# D2522AA register map
Vendor: Dialog; Series: D2522AA; File version: 1.2
CPU: CM0 r1p0, little endian, MPU, FPU, 3 interrupt priority bits
Registers are 32-bit, read-write, reset 0x0 unless marked. A register's access mark holds for its fields unless they carry their own. Offsets are from the block's base; [hi:lo] are bit positions; 'fields as' and 'values as' point back to an identical list.

## CMAC_TIMER_SLP — CMAC_TIMER_SLP registers
Base 0x50010400
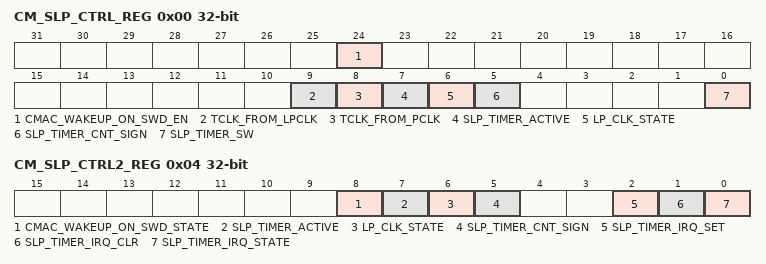
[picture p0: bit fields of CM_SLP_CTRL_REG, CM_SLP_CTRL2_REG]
0x00 CM_SLP_CTRL_REG — CMAC Sleep Control 1 (allowed to RMW)
  [24] CMAC_WAKEUP_ON_SWD_EN — If '1' then enable the generation of CMAC_WAKEUP_ON_SWD.
  [9] TCLK_FROM_LPCLK — The FW must be synchronized with LP_CLK negedge in order to change this bit.
  [8] TCLK_FROM_PCLK — The FW must be synchronized with LP_CLK negedge in order to change this bit.
  [7] SLP_TIMER_ACTIVE ro
  [6] LP_CLK_STATE ro — Current state of LP_CLK. Typically used only by System CPU. Refer also to CM_EV_LATCHED_REG->EV1C_LP_CLK_* and CM_SLP_CTRL2_REG->LP_CLK_STATE.
  [5] SLP_TIMER_CNT_SIGN ro — Refer to CM_SLP_CTRL2_REG->SLP_TIMER_CNT_SIGN.
  [0] SLP_TIMER_SW — The FW must be synchronized with LP_CLK negedge in order to change this bit. If 1: Initiate the sequence of stop counting with LL_TIMERx and start counting with the Sleep Timer. If 0: Initiate the sequence of stop counting with Sleep Timer and start counting with the LL_TIMERx. Writing a "1" will be effective only if SLP_TIMER_SEL_PCLK is written also with "0", regardless of the previous state of SLP_TIMER_SEL_PCLK. Writing a "0" will be effective only if SLP_TIMER_SEL_PCLK is written also with "1", regardless of the previous state of SLP_TIMER_SEL_PCLK. The end of the sequence is reported via SLP_TIMER_ACTIVE.
0x04 CM_SLP_CTRL2_REG — CMAC Sleep Control 2 (no RMW)
  [8] CMAC_WAKEUP_ON_SWD_STATE — Provides the current state of CMAC_WAKEUP_ON_SWD. Writing '1' will clear this bit. Writing '0' has no effect. When CM_SLP_CTRL_REG->CMAC_WAKEUP_ON_SWD_EN=1 and the Radio Power Domain is down and SYS_CTRL_REG->CMAC_DEBUGGER_ENABLE=1 then any negative edge on SWDCLK pin will set the CMAC_WAKEUP_ON_SWD. The CMAC_WAKEUP_ON_SWD logically OR-ed with SLP_TIMER_IRQ is connected to PDC and thus it is able to wake up the CMAC, allowing the connection of CMAC Cortex with the debugger.
  [7] SLP_TIMER_ACTIVE ro — Refer to CM_SLP_CTRL_REG->SLP_TIMER_ACTIVE
  [6] LP_CLK_STATE ro — Refer to CM_SLP_CTRL_REG->LP_CLK_STATE.
  [5] SLP_TIMER_CNT_SIGN ro — Provides the SLP_TIMER_CNT[32] bit, which corresponds to the sign bit.
  [2] SLP_TIMER_IRQ_SET — Writing '1' will cause the IRQ to be set. This field remains to '1' until the IRQ is set. Writing '0' has no effect. System CPU SW may use this field to force CMAC to wakeup through SLP_TIMER. Note that typically SW wakes up CMAC through the SYS2CMAC_IRQ (via PDC).
  [1] SLP_TIMER_IRQ_CLR — Writing '1' will cause the IRQ to be cleared. This field remains to '1' until the IRQ is cleared. Writing '0' has no effect. Note that clearing the IRQ is not possible as long as the Timer is "1", since the Expire event has higher priority.
  [0] SLP_TIMER_IRQ_STATE ro — Provides the current state of the CMAC Sleep Timer IRQ.
0x08 CM_SLP_TIMER_REG (reset mask 0x7FFFFFFF) — CMAC Sleep Timer
  [31:0] CM_SLP_TIMER_VALUE — The low 32 bits of the signed value of the 33 bit CMAC Sleep Timer. The sign bit 32 can be fetched via CM_SLP_CTRL_REG->SLP_TIMER_CNT_SIGN. It's possible to perform only 32-bit write access, while every write access will set the sign bit 32 to '0'. A read or write access with CM_SLP_CTRL_REG->TCLK_FROM_PCLK equal to 0 will cause a bus error. As long as the value is "1" then the expiration and the IRQ signal are asserted.

## CRG_COM — CRG_COM registers
Base 0x50020900
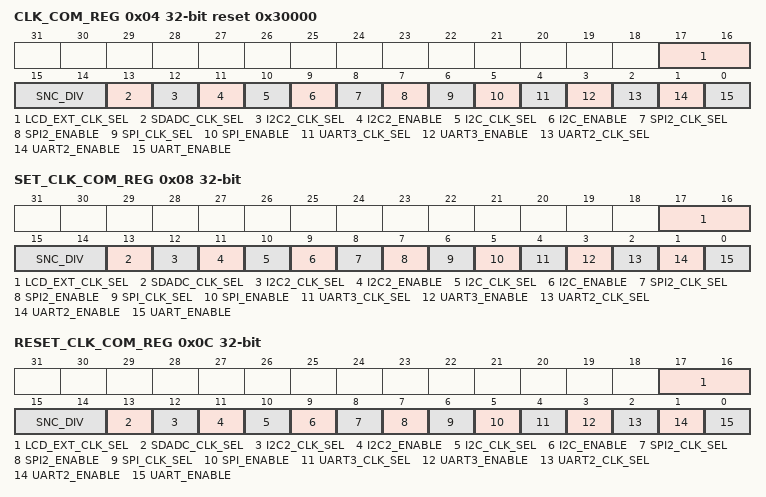
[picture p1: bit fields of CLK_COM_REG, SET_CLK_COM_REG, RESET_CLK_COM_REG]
0x04 CLK_COM_REG reset 0x30000 — Peripheral divider register
  [17:16] LCD_EXT_CLK_SEL — Select LCD external clock speed. 0x0: 1 Hz 0x1: 62.5 Hz 0x2: 125 Hz 0x3: off
  [15:14] SNC_DIV — Division factor for SNC, w.r.t. pclk setting 0x0 = divide by 1 0x1 = divide by 2 0x2 = divide by 4 0x3 = divide by 8
  [13] SDADC_CLK_SEL — Selects the clock source 1 = DIV1 clock 0 = DIVN clock
  [12] I2C2_CLK_SEL — Selects the clock source 1 = DIV1 clock 0 = DIVN clock
  [11] I2C2_ENABLE — Enables the clock
  [10] I2C_CLK_SEL — Selects the clock source 1 = DIV1 clock 0 = DIVN clock
  [9] I2C_ENABLE — Enables the clock
  [8] SPI2_CLK_SEL — Selects the clock source 1 = DIV1 clock 0 = DIVN clock
  [7] SPI2_ENABLE — Enables the clock
  [6] SPI_CLK_SEL — Selects the clock source 1 = DIV1 clock 0 = DIVN clock
  [5] SPI_ENABLE — Enables the clock
  [4] UART3_CLK_SEL — Selects the clock source 1 = DIV1 clock 0 = DIVN clock
  [3] UART3_ENABLE — Enables the clock
  [2] UART2_CLK_SEL — Selects the clock source 1 = DIV1 clock 0 = DIVN clock
  [1] UART2_ENABLE — Enables the clock
  [0] UART_ENABLE — Enables the clock
0x08 SET_CLK_COM_REG — Peripheral divider register SET register. Reads back 0x0000
  [17:16] LCD_EXT_CLK_SEL rw-once — Select LCD external clock speed. 0x0: 1 Hz 0x1: 62.5 Hz 0x2: 125 Hz 0x3: off
  [15:14] SNC_DIV rw-once — Division factor for SNC, w.r.t. pclk setting 0x0 = divide by 1 0x1 = divide by 2 0x2 = divide by 4 0x3 = divide by 8
  [13] SDADC_CLK_SEL rw-once — Selects the clock source 1 = DIV1 clock 0 = DIVN clock
  [12] I2C2_CLK_SEL rw-once — Selects the clock source 1 = DIV1 clock 0 = DIVN clock
  [11] I2C2_ENABLE rw-once — Enables the clock
  [10] I2C_CLK_SEL rw-once — Selects the clock source 1 = DIV1 clock 0 = DIVN clock
  [9] I2C_ENABLE rw-once — Enables the clock
  [8] SPI2_CLK_SEL rw-once — Selects the clock source 1 = DIV1 clock 0 = DIVN clock
  [7] SPI2_ENABLE rw-once — Enables the clock
  [6] SPI_CLK_SEL rw-once — Selects the clock source 1 = DIV1 clock 0 = DIVN clock
  [5] SPI_ENABLE rw-once — Enables the clock
  [4] UART3_CLK_SEL rw-once — Selects the clock source 1 = DIV1 clock 0 = DIVN clock
  [3] UART3_ENABLE rw-once — Enables the clock
  [2] UART2_CLK_SEL rw-once — Selects the clock source 1 = DIV1 clock 0 = DIVN clock
  [1] UART2_ENABLE rw-once — Enables the clock
  [0] UART_ENABLE rw-once — Enables the clock
0x0C RESET_CLK_COM_REG — Peripheral divider register RESET register. Reads back 0x0000
  fields as CLK_COM_REG
